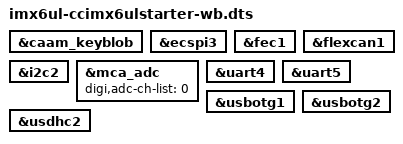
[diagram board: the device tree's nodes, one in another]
/*
 * Copyright 2016 Digi International, Inc.
 *
 * The code contained herein is licensed under the GNU General Public
 * License. You may obtain a copy of the GNU General Public License
 * Version 2 or later at the following locations:
 *
 * http://www.opensource.org/licenses/gpl-license.html
 * http://www.gnu.org/copyleft/gpl.html
 */

/dts-v1/;
#include <dt-bindings/input/input.h>
#include <dt-bindings/interrupt-controller/irq.h>
/* i.MX6 UltraLite CPU */
#include "imx6ul.dtsi"
/* ConnectCore 6UL (wireless/bluetooth variant) */
#include "imx6ul-ccimx6ul-wb.dtsi"
/* ConnectCore 6UL StarterBoard */
#include "imx6ul-ccimx6ulstarter.dtsi"

&caam_keyblob {
	status = "okay";
};

/* ECSPI3 (Raspberry PI Expansion header) */
&ecspi3 {
	/*
	 * There are no SPI slave devices on the SBC.
	 * Enable if adding your slave devices below.
	 */
	//status = "okay";

	/* Add your slave devices here. Next is an example of spidev. */
	//spidev@0 {
	//	reg = <0>;
	//	compatible = "spidev";
	//	spi-max-frequency = <1000000>;
	//};
};

&fec1 {
	status = "okay";
};

/* CAN1 (Raspberry PI Expansion header) */
&flexcan1 {
	status = "okay";
};

/* I2C2 (Raspberry PI Expansion header and Grove connector) */
&i2c2 {
	status = "okay";
};

/* MCA IO0 connected to Grove ADC connector */
&mca_adc {
	digi,adc-ch-list = <0>;
};

/* UART4 (Raspberry PI Expansion header) */
&uart4 {
	status = "okay";
};

/* UART5 (Console) */
&uart5 {
	status = "okay";
};

&usbotg1 {
	status = "okay";
};

&usbotg2 {
	status = "okay";
};

/* USDHC2 (microSD) */
&usdhc2 {
	status = "okay";
};
